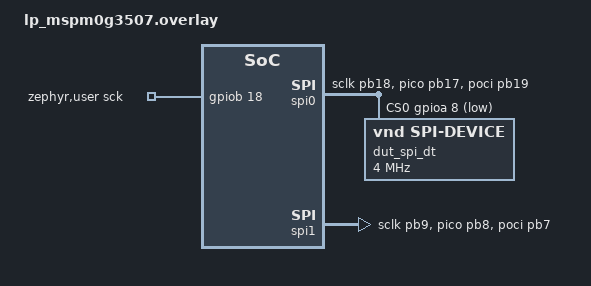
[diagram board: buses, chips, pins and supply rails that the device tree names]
/*
 * Copyright (c) 2026 Linumiz
 *
 * SPDX-License-Identifier: Apache-2.0
 */
 / {
	zephyr,user {
		sck-gpios = <&gpiob 18 GPIO_ACTIVE_HIGH>;
	};
};

&spi0 {
   	status = "okay";
    	pinctrl-0 = <&spi0_sclk_pb18 &spi0_pico_pb17 &spi0_poci_pb19>;
	pinctrl-names = "default";
	cs-gpios = <&gpioa 8 GPIO_ACTIVE_LOW>;
	interrupts = <9 1>;

	dut_spi_dt: test-spi-dev@0 {
		compatible = "vnd,spi-device";
		reg = <0>;
		spi-max-frequency = <4000000>;
	};
};

dut_spis: &spi1 {
	status = "okay";
	pinctrl-0 = <&spi1_sclk_pb9 &spi1_pico_pb8 &spi1_poci_pb7>;
	pinctrl-names = "default";
	cs-gpios = <&gpiob 6 GPIO_ACTIVE_LOW>;
	interrupts = <10 0>;
};
